# UNIONSYNTH register map
Vendor: SYNTH-Corp; File version: 1.0
CMSIS union/array style fixture
CPU: CM0 r0p1, little endian
Registers are 32-bit, access not given, reset 0x0 unless marked. A register's access mark holds for its fields unless they carry their own. Offsets are from the block's base; lines under a group give offsets from that group; [hi:lo] are bit positions; {n}, {i} and the like mark numbered series; 'fields as' and 'values as' point back to an identical list; <NAME> marks a mode.

## Memory map
0x40001800 EIC size 0x100 — External interrupt controller
0x41004400 PORT size 0x100 — Port groups
0x42000800 SERCOM0 size 0x100 — Serial communication interface 0

## PORT — Port groups
Base 0x41004400
0x00 DIR0
0x04 DIRSET0 — Port A direction set
0x08 DIRSET1 — Port B direction set
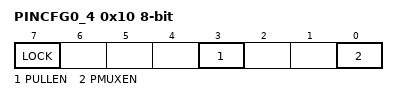
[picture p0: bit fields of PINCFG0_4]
0x10 PINCFG0_4 8-bit — Port A pin 4 config
  [7] LOCK ro — Pin lock (read-only)
  [3] PULLEN
  [0] PMUXEN
0x14 PINCFG1_4 8-bit — Port B pin 4 config
0x20 OUT0 — Port A data output
0x24 OUTSET0 — Port A data output set
0x28 OUTCLR0 — Port A data output clear
0x2C OUTTGL0 — Port A data output toggle
0x30 OUT0_XOR — Port A data output XOR (RP2040 style)

## SERCOM0 — Serial communication interface 0
Base 0x42000800
0x00 USART.CTRLA — USART control A
0x04 USART.CTRLB — USART control B

## EIC — External interrupt controller
Base 0x40001800
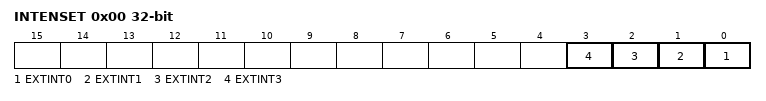
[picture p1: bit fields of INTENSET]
0x00 INTENSET — Interrupt enable set
  [n] EXTINT{n} (n=0..3)
0x18 CONFIG0
0x1C CONFIG1
